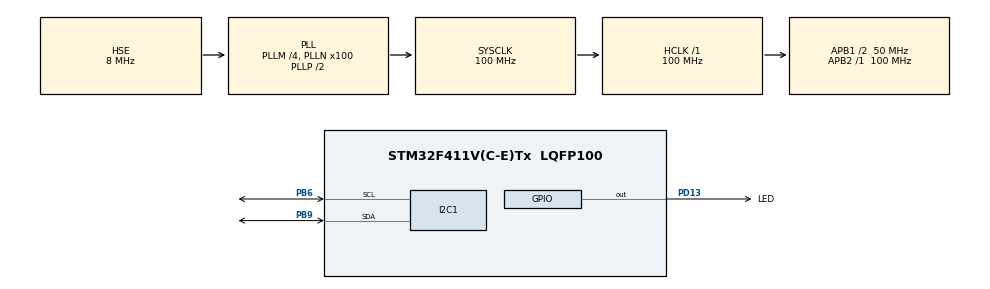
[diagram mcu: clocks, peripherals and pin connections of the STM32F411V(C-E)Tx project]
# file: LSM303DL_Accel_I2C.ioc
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Mcu.Family=STM32F4
Mcu.Name=STM32F411V(C-E)Tx
Mcu.Package=LQFP100
NVIC.PriorityGroup=NVIC_PRIORITYGROUP_4
PA13.Mode=Serial_Wire
PA13.Signal=SYS_JTMS-SWDIO
PA14.Mode=Serial_Wire
PA14.Signal=SYS_JTCK-SWCLK
PB6.GPIO_Pu=GPIO_PULLUP
PB6.Mode=I2C
PB6.Signal=I2C1_SCL
PB9.GPIO_Pu=GPIO_PULLUP
PB9.Mode=I2C
PB9.Signal=I2C1_SDA
PD13.GPIO_Label=LED
PD13.Signal=GPIO_Output
PH0\ -\ OSC_IN.Mode=HSE-External-Oscillator
PH0\ -\ OSC_IN.Signal=RCC_OSC_IN
PH1\ -\ OSC_OUT.Mode=HSE-External-Oscillator
PH1\ -\ OSC_OUT.Signal=RCC_OSC_OUT
ProjectManager.HeapSize=0x200
ProjectManager.StackSize=0x400
ProjectManager.TargetToolchain=STM32CubeIDE
RCC.48MHZClocksFreq_Value=50000000
RCC.AHBFreq_Value=100000000
RCC.APB1CLKDivider=RCC_HCLK_DIV2
RCC.APB1Freq_Value=50000000
RCC.APB1TimFreq_Value=100000000
RCC.APB2Freq_Value=100000000
RCC.APB2TimFreq_Value=100000000
RCC.CortexFreq_Value=100000000
RCC.HCLKFreq_Value=100000000
RCC.HSE_VALUE=8000000
RCC.HSI_VALUE=16000000
RCC.LSE_VALUE=32768
RCC.PLLM=4
RCC.PLLN=100
RCC.PLLSourceVirtual=RCC_PLLSOURCE_HSE
RCC.SYSCLKFreq_VALUE=100000000
RCC.SYSCLKSource=RCC_SYSCLKSOURCE_PLLCLK
RCC.VCOOutputFreq_Value=200000000
board=custom

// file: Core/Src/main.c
/* USER CODE BEGIN Header */
/**
  ******************************************************************************
  * @file           : main.c
  * @brief          : Main program body
  ******************************************************************************
  * @attention
  *
  * Copyright (c) 2024 STMicroelectronics.
  * All rights reserved.
  *
  * This software is licensed under terms that can be found in the LICENSE file
  * in the root directory of this software component.
  * If no LICENSE file comes with this software, it is provided AS-IS.
  *
  ******************************************************************************
  */
/* USER CODE END Header */
#include "main.h"

/* USER CODE BEGIN Includes */
#include "LSM303DL.h"
/* USER CODE END Includes */

I2C_HandleTypeDef hi2c1;

/* USER CODE BEGIN PV */
LSM303DLTypeDef LSM303DL;

uint8_t isInitialized = 0x00;
uint8_t LSM303DL_Buffer[10];
volatile int16_t Accel_RawData[3];
/* USER CODE END PV */

void SystemClock_Config(void);
static void MX_GPIO_Init(void);
static void MX_I2C1_Init(void);
/* USER CODE BEGIN PFP */
void Accel_LSM303DL_Init(void);
void Accel_LSM303DL_ReadData(void);
/* USER CODE END PFP */

int main(void)
{

  /* MCU Configuration--------------------------------------------------------*/

  /* Reset of all peripherals, Initializes the Flash interface and the Systick. */
  HAL_Init();

  /* Configure the system clock */
  SystemClock_Config();

  /* Initialize all configured peripherals */
  MX_GPIO_Init();
  MX_I2C1_Init();
  /* USER CODE BEGIN 2 */
  Accel_LSM303DL_Init();
  /* USER CODE END 2 */

  /* Infinite loop */
  while (1)
  {

    /* USER CODE BEGIN 3 */
	  Accel_LSM303DL_ReadData();
	  HAL_GPIO_TogglePin(LED_GPIO_Port, LED_Pin);
  }
  /* USER CODE END 3 */
}

void SystemClock_Config(void)
{
  RCC_OscInitTypeDef RCC_OscInitStruct = {0};
  RCC_ClkInitTypeDef RCC_ClkInitStruct = {0};

  /** Configure the main internal regulator output voltage
  */
  __HAL_RCC_PWR_CLK_ENABLE();
  __HAL_PWR_VOLTAGESCALING_CONFIG(PWR_REGULATOR_VOLTAGE_SCALE1);

  /** Initializes the RCC Oscillators according to the specified parameters
  * in the RCC_OscInitTypeDef structure.
  */
  RCC_OscInitStruct.OscillatorType = RCC_OSCILLATORTYPE_HSE;
  RCC_OscInitStruct.HSEState = RCC_HSE_ON;
  RCC_OscInitStruct.PLL.PLLState = RCC_PLL_ON;
  RCC_OscInitStruct.PLL.PLLSource = RCC_PLLSOURCE_HSE;
  RCC_OscInitStruct.PLL.PLLM = 4;
  RCC_OscInitStruct.PLL.PLLN = 100;
  RCC_OscInitStruct.PLL.PLLP = RCC_PLLP_DIV2;
  RCC_OscInitStruct.PLL.PLLQ = 4;
  if (HAL_RCC_OscConfig(&RCC_OscInitStruct) != HAL_OK)
  {
    Error_Handler();
  }

  /** Initializes the CPU, AHB and APB buses clocks
  */
  RCC_ClkInitStruct.ClockType = RCC_CLOCKTYPE_HCLK|RCC_CLOCKTYPE_SYSCLK
                              |RCC_CLOCKTYPE_PCLK1|RCC_CLOCKTYPE_PCLK2;
  RCC_ClkInitStruct.SYSCLKSource = RCC_SYSCLKSOURCE_PLLCLK;
  RCC_ClkInitStruct.AHBCLKDivider = RCC_SYSCLK_DIV1;
  RCC_ClkInitStruct.APB1CLKDivider = RCC_HCLK_DIV2;
  RCC_ClkInitStruct.APB2CLKDivider = RCC_HCLK_DIV1;

  if (HAL_RCC_ClockConfig(&RCC_ClkInitStruct, FLASH_LATENCY_3) != HAL_OK)
  {
    Error_Handler();
  }
}

static void MX_I2C1_Init(void)
{

  hi2c1.Instance = I2C1;
  hi2c1.Init.ClockSpeed = 100000;
  hi2c1.Init.DutyCycle = I2C_DUTYCYCLE_2;
  hi2c1.Init.OwnAddress1 = 0;
  hi2c1.Init.AddressingMode = I2C_ADDRESSINGMODE_7BIT;
  hi2c1.Init.DualAddressMode = I2C_DUALADDRESS_DISABLE;
  hi2c1.Init.OwnAddress2 = 0;
  hi2c1.Init.GeneralCallMode = I2C_GENERALCALL_DISABLE;
  hi2c1.Init.NoStretchMode = I2C_NOSTRETCH_DISABLE;
  if (HAL_I2C_Init(&hi2c1) != HAL_OK)
  {
    Error_Handler();
  }

}

static void MX_GPIO_Init(void)
{
  GPIO_InitTypeDef GPIO_InitStruct = {0};

  /* GPIO Ports Clock Enable */
  __HAL_RCC_GPIOH_CLK_ENABLE();
  __HAL_RCC_GPIOD_CLK_ENABLE();
  __HAL_RCC_GPIOA_CLK_ENABLE();
  __HAL_RCC_GPIOB_CLK_ENABLE();

  /*Configure GPIO pin Output Level */
  HAL_GPIO_WritePin(LED_GPIO_Port, LED_Pin, GPIO_PIN_RESET);

  /*Configure GPIO pin : LED_Pin */
  GPIO_InitStruct.Pin = LED_Pin;
  GPIO_InitStruct.Mode = GPIO_MODE_OUTPUT_PP;
  GPIO_InitStruct.Pull = GPIO_NOPULL;
  GPIO_InitStruct.Speed = GPIO_SPEED_FREQ_LOW;
  HAL_GPIO_Init(LED_GPIO_Port, &GPIO_InitStruct);

}

/* USER CODE BEGIN 4 */
// <---- ------------ Accelometer Initialize ------------ ---->
void Accel_LSM303DL_Init(void)
{
	LSM303DL.Accel_PWR 				= LSM303DLHC_NORMAL_MODE;
	LSM303DL.Accel_DataRate 		= LSM303DLHC_ODR_1344_HZ;
	LSM303DL.Accel_Axes 			= LSM303DLHC_AXES_ENABLE;
	LSM303DL.Accel_HighResEn 		= LSM303DLHC_HR_DISABLE;
	LSM303DL.Accel_Scale 			= LSM303DLHC_FULLSCALE_16G;
	LSM303DL.Accel_FilterMode 		= LSM303DLHC_HPM_NORMAL_MODE_RES;
	LSM303DL.Accel_FilterCutFreq 	= LSM303DLHC_HPFCF_8;

	isInitialized = LSM303DL_Init(&hi2c1, &LSM303DL);
	if(isInitialized != LSM303DL_RESULT_OK)
		Error_Handler();
}

// <---- ------------ Accelometer Read Data ------------ ---->
void Accel_LSM303DL_ReadData(void)
{
	LSM303DL_ReadData(&hi2c1, LSM303DL_Buffer, LSM303DLHC_OUT_X_L_A, 6);

	Accel_RawData[0] = (int16_t)(LSM303DL_Buffer[0] | LSM303DL_Buffer[1] << 8);
	Accel_RawData[1] = (int16_t)(LSM303DL_Buffer[2] | LSM303DL_Buffer[3] << 8);
	Accel_RawData[2] = (int16_t)(LSM303DL_Buffer[4] | LSM303DL_Buffer[5] << 8);
}
/* USER CODE END 4 */

void Error_Handler(void)
{
  __disable_irq();
  while (1)
  {
  }
}
